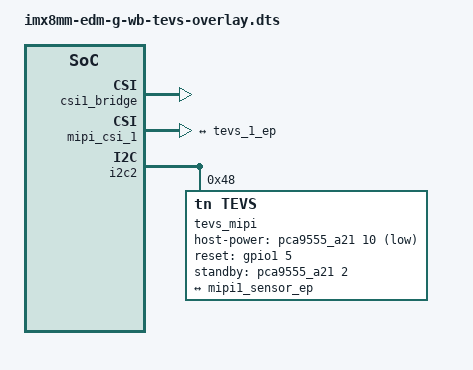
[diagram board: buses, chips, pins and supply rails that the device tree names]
// SPDX-License-Identifier: (GPL-2.0+ OR MIT)
/*
 * Copyright 2024 TechNexion Ltd.
 *
 * Author: Nian Yang <nian.yang@technexion.com>
 *
 */

/dts-v1/;
/plugin/;

#include <dt-bindings/interrupt-controller/irq.h>
#include <dt-bindings/clock/imx8mm-clock.h>
#include <dt-bindings/gpio/gpio.h>

/ {
	fragment@0 {
		target = <&csi1_bridge>;
		__overlay__ {
			status = "okay";
		};
	};

	fragment@1 {
		target = <&mipi_csi_1>;
		__overlay__ {
			status = "okay";
			#address-cells = <1>;
			#size-cells = <0>;

			port {
				mipi1_sensor_ep: endpoint@1 {
					remote-endpoint = <&tevs_1_ep>;
					data-lanes = <4>;
					csis-hs-settle = <19>;
					csis-clk-settle = <2>;
					csis-wclk;
				};
			};
		};
	};

	fragment@2 {
		target = <&i2c2>;
		__overlay__ {
			#address-cells = <1>;
			#size-cells = <0>;
			status = "okay";

			tevs_mipi: tevs_mipi@48 {
				compatible = "tn,tevs";
				reg = <0x48>;

				pinctrl-names = "default";
				pinctrl-0 = <&pinctrl_csi_rst>;
				host-power-gpios = <&pca9555_a21 10 GPIO_ACTIVE_LOW>;
				reset-gpios = <&gpio1 5 GPIO_ACTIVE_HIGH>;
				standby-gpios = <&pca9555_a21 2 GPIO_ACTIVE_HIGH>;
				data-lanes = <4>;
				// data-frequency = <800>;
				continuous-clock = <0>;
				supports-over-4k-res;
				status = "okay";

				port {
					tevs_1_ep: endpoint {
						remote-endpoint = <&mipi1_sensor_ep>;
					};
				};
			};
		};
	};
};
